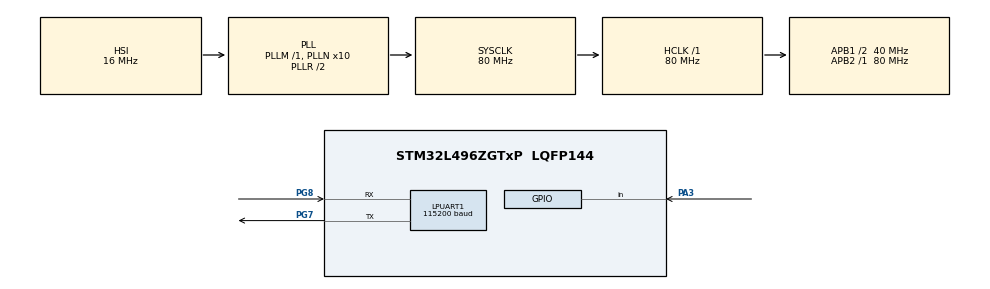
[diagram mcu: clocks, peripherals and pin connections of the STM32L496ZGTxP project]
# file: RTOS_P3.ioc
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FREERTOS.Queues01=messageQueue,10,uint32_t,0,Dynamic,NULL,NULL
FREERTOS.Tasks01=Task1,24,128,StartTask1,Default,NULL,Dynamic,NULL,NULL;Task2,24,128,StartTask2,Default,NULL,Dynamic,NULL,NULL;RxTask,25,512,StartRxTask,Default,NULL,Dynamic,NULL,NULL
FREERTOS.configTOTAL_HEAP_SIZE=5000
FREERTOS.configUSE_NEWLIB_REENTRANT=1
LPUART1.BaudRate=115200
LPUART1.WordLength=UART_WORDLENGTH_8B
Mcu.Family=STM32L4
Mcu.Name=STM32L496ZGTxP
Mcu.Package=LQFP144
NVIC.PriorityGroup=NVIC_PRIORITYGROUP_4
NVIC.TIM6_DAC_IRQn=true\:15\:0\:false\:false\:true\:false\:false\:true\:true
NVIC.TimeBase=TIM6_DAC_IRQn
NVIC.TimeBaseIP=TIM6
PA13\ (JTMS/SWDIO).Mode=Serial_Wire
PA13\ (JTMS/SWDIO).Signal=SYS_JTMS-SWDIO
PA14\ (JTCK/SWCLK).Mode=Serial_Wire
PA14\ (JTCK/SWCLK).Signal=SYS_JTCK-SWCLK
PA3.GPIO_PuPd=GPIO_PULLUP
PA3.Signal=GPIO_Input
PG7.Mode=Asynchronous
PG7.Signal=LPUART1_TX
PG8.Mode=Asynchronous
PG8.Signal=LPUART1_RX
ProjectManager.HeapSize=0x200
ProjectManager.StackSize=0x400
ProjectManager.TargetToolchain=STM32CubeIDE
RCC.48MHZClocksFreq_Value=24000000
RCC.ADCFreq_Value=64000000
RCC.AHBFreq_Value=80000000
RCC.APB1CLKDivider=RCC_HCLK_DIV2
RCC.APB1Freq_Value=40000000
RCC.APB1TimFreq_Value=80000000
RCC.APB2Freq_Value=80000000
RCC.APB2TimFreq_Value=80000000
RCC.CortexFreq_Value=80000000
RCC.HCLKFreq_Value=80000000
RCC.HSE_VALUE=8000000
RCC.HSI48_VALUE=48000000
RCC.HSI_VALUE=16000000
RCC.LSE_VALUE=32768
RCC.MSI_VALUE=4000000
RCC.PLLMUL=RCC_PLL_MUL9
RCC.PLLN=10
RCC.PLLSourceVirtual=RCC_PLLSOURCE_HSI
RCC.PRESCALERUSB=RCC_USBCLKSOURCE_PLL_DIV1_5
RCC.SYSCLKFreq_VALUE=80000000
RCC.SYSCLKSource=RCC_SYSCLKSOURCE_PLLCLK
RCC.SYSCLKSourceVirtual=RCC_SYSCLKSOURCE_PLLCLK
RCC.USBFreq_Value=64000000
RCC.VCOOutputFreq_Value=160000000
VP_FREERTOS_VS_CMSIS_V2.Mode=CMSIS_V2
VP_SYS_VS_tim6.Mode=TIM6
board=NUCLEO-L496ZG-P

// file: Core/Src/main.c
/* USER CODE BEGIN Header */
/**
  ******************************************************************************
  * @file           : main.c
  * @brief          : Main program body
  ******************************************************************************
  * @attention
  *
  * Copyright (c) 2026 STMicroelectronics.
  * All rights reserved.
  *
  * This software is licensed under terms that can be found in the LICENSE file
  * in the root directory of this software component.
  * If no LICENSE file comes with this software, it is provided AS-IS.
  *
  ******************************************************************************
  */
/* USER CODE END Header */
#include "main.h"
#include "cmsis_os.h"

/* USER CODE BEGIN Includes */
#include "stdio.h"
/* USER CODE END Includes */

UART_HandleTypeDef hlpuart1;

/* Definitions for Task1 */
osThreadId_t Task1Handle;
const osThreadAttr_t Task1_attributes = {
  .name = "Task1",
  .stack_size = 128 * 4,
  .priority = (osPriority_t) osPriorityNormal,
};
/* Definitions for Task2 */
osThreadId_t Task2Handle;
const osThreadAttr_t Task2_attributes = {
  .name = "Task2",
  .stack_size = 128 * 4,
  .priority = (osPriority_t) osPriorityNormal,
};
/* Definitions for RxTask */
osThreadId_t RxTaskHandle;
const osThreadAttr_t RxTask_attributes = {
  .name = "RxTask",
  .stack_size = 512 * 4,
  .priority = (osPriority_t) osPriorityNormal1,
};
/* Definitions for messageQueue */
osMessageQueueId_t messageQueueHandle;
const osMessageQueueAttr_t messageQueue_attributes = {
  .name = "messageQueue"
};

void SystemClock_Config(void);
static void MX_GPIO_Init(void);
static void MX_LPUART1_UART_Init(void);
void StartTask1(void *argument);
void StartTask2(void *argument);
void StartRxTask(void *argument);

/* USER CODE BEGIN 0 */
typedef struct {
	uint8_t event_id;
	uint32_t timestamp;
} messageQueue_t;

int __io_putchar (int ch)
{
	uint8_t c = ch;
	HAL_UART_Transmit(&hlpuart1, &c, 1, HAL_MAX_DELAY);
	return ch;
}

/* USER CODE END 0 */

int main(void)
{

  /* MCU Configuration--------------------------------------------------------*/

  /* Reset of all peripherals, Initializes the Flash interface and the Systick. */
  HAL_Init();

  /* Configure the system clock */
  SystemClock_Config();

  /* Initialize all configured peripherals */
  MX_GPIO_Init();
  MX_LPUART1_UART_Init();

  /* Init scheduler */
  osKernelInitialize();

  /* Create the queue(s) */
  /* creation of messageQueue */
  messageQueueHandle = osMessageQueueNew (10, sizeof(messageQueue_t), &messageQueue_attributes);

  /* Create the thread(s) */
  /* creation of Task1 */
  Task1Handle = osThreadNew(StartTask1, NULL, &Task1_attributes);

  /* creation of Task2 */
  Task2Handle = osThreadNew(StartTask2, NULL, &Task2_attributes);

  /* creation of RxTask */
  RxTaskHandle = osThreadNew(StartRxTask, NULL, &RxTask_attributes);

  /* Start scheduler */
  osKernelStart();

  /* We should never get here as control is now taken by the scheduler */

  /* Infinite loop */
  while (1)
  {

  }
}

void SystemClock_Config(void)
{
  RCC_OscInitTypeDef RCC_OscInitStruct = {0};
  RCC_ClkInitTypeDef RCC_ClkInitStruct = {0};

  /** Configure the main internal regulator output voltage
  */
  if (HAL_PWREx_ControlVoltageScaling(PWR_REGULATOR_VOLTAGE_SCALE1) != HAL_OK)
  {
    Error_Handler();
  }

  /** Initializes the RCC Oscillators according to the specified parameters
  * in the RCC_OscInitTypeDef structure.
  */
  RCC_OscInitStruct.OscillatorType = RCC_OSCILLATORTYPE_HSI;
  RCC_OscInitStruct.HSIState = RCC_HSI_ON;
  RCC_OscInitStruct.HSICalibrationValue = RCC_HSICALIBRATION_DEFAULT;
  RCC_OscInitStruct.PLL.PLLState = RCC_PLL_ON;
  RCC_OscInitStruct.PLL.PLLSource = RCC_PLLSOURCE_HSI;
  RCC_OscInitStruct.PLL.PLLM = 1;
  RCC_OscInitStruct.PLL.PLLN = 10;
  RCC_OscInitStruct.PLL.PLLP = RCC_PLLP_DIV2;
  RCC_OscInitStruct.PLL.PLLQ = RCC_PLLQ_DIV2;
  RCC_OscInitStruct.PLL.PLLR = RCC_PLLR_DIV2;
  if (HAL_RCC_OscConfig(&RCC_OscInitStruct) != HAL_OK)
  {
    Error_Handler();
  }

  /** Initializes the CPU, AHB and APB buses clocks
  */
  RCC_ClkInitStruct.ClockType = RCC_CLOCKTYPE_HCLK|RCC_CLOCKTYPE_SYSCLK
                              |RCC_CLOCKTYPE_PCLK1|RCC_CLOCKTYPE_PCLK2;
  RCC_ClkInitStruct.SYSCLKSource = RCC_SYSCLKSOURCE_PLLCLK;
  RCC_ClkInitStruct.AHBCLKDivider = RCC_SYSCLK_DIV1;
  RCC_ClkInitStruct.APB1CLKDivider = RCC_HCLK_DIV2;
  RCC_ClkInitStruct.APB2CLKDivider = RCC_HCLK_DIV1;

  if (HAL_RCC_ClockConfig(&RCC_ClkInitStruct, FLASH_LATENCY_4) != HAL_OK)
  {
    Error_Handler();
  }
}

static void MX_LPUART1_UART_Init(void)
{

  hlpuart1.Instance = LPUART1;
  hlpuart1.Init.BaudRate = 115200;
  hlpuart1.Init.WordLength = UART_WORDLENGTH_8B;
  hlpuart1.Init.StopBits = UART_STOPBITS_1;
  hlpuart1.Init.Parity = UART_PARITY_NONE;
  hlpuart1.Init.Mode = UART_MODE_TX_RX;
  hlpuart1.Init.HwFlowCtl = UART_HWCONTROL_NONE;
  hlpuart1.Init.OneBitSampling = UART_ONE_BIT_SAMPLE_DISABLE;
  hlpuart1.AdvancedInit.AdvFeatureInit = UART_ADVFEATURE_NO_INIT;
  if (HAL_UART_Init(&hlpuart1) != HAL_OK)
  {
    Error_Handler();
  }

}

static void MX_GPIO_Init(void)
{
  GPIO_InitTypeDef GPIO_InitStruct = {0};

  /* GPIO Ports Clock Enable */
  __HAL_RCC_GPIOA_CLK_ENABLE();
  __HAL_RCC_GPIOG_CLK_ENABLE();
  HAL_PWREx_EnableVddIO2();

  /*Configure GPIO pin : PA3 */
  GPIO_InitStruct.Pin = GPIO_PIN_3;
  GPIO_InitStruct.Mode = GPIO_MODE_INPUT;
  GPIO_InitStruct.Pull = GPIO_PULLUP;
  HAL_GPIO_Init(GPIOA, &GPIO_InitStruct);

}

void StartTask1(void *argument)
{
  /* USER CODE BEGIN 5 */
	messageQueue_t msg;

  /* Infinite loop */
  for(;;)
  {
	  if (HAL_GPIO_ReadPin(GPIOA, GPIO_PIN_3) == 0)
	  {
		  msg.event_id = 0x01;
		  msg.timestamp = HAL_GetTick();
		  osMessageQueuePut(messageQueueHandle, &msg, 0, 0);
		  osDelay(200);  // debounce
	  }
	  osDelay(20);
  }
  /* USER CODE END 5 */
}

void StartTask2(void *argument)
{
  /* USER CODE BEGIN StartTask2 */
	messageQueue_t msg;
  /* Infinite loop */
  for(;;)
  {
	  msg.event_id = 0x02;
	  msg.timestamp = HAL_GetTick()/1000;  // in seconds
	  osMessageQueuePut(messageQueueHandle, &msg, 0, 0);
	  osDelay(1000);
  }
  /* USER CODE END StartTask2 */
}

void StartRxTask(void *argument)
{
  /* USER CODE BEGIN StartRxTask */
	messageQueue_t msg;
  /* Infinite loop */
  for(;;)
  {
	  if (osMessageQueueGet(messageQueueHandle, &msg, 0, osWaitForever) == osOK)
	  {
		  printf ("Event ID: %d, Timestamp: %lu\n", msg.event_id, msg.timestamp);
	  }
    osDelay(1);
  }
  /* USER CODE END StartRxTask */
}

void HAL_TIM_PeriodElapsedCallback(TIM_HandleTypeDef *htim)
{
  if (htim->Instance == TIM6)
  {
    HAL_IncTick();
  }
}

void Error_Handler(void)
{
  __disable_irq();
  while (1)
  {
  }
}
